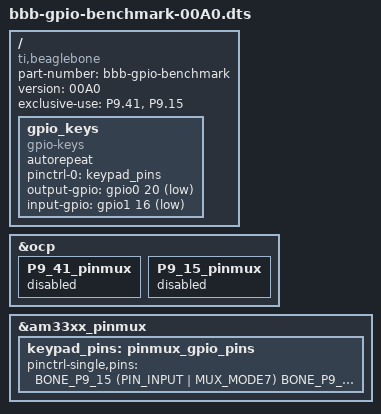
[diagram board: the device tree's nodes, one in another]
/dts-v1/;
/plugin/;        

#include <dt-bindings/board/am335x-bbw-bbb-base.h>
#include <dt-bindings/gpio/gpio.h>
#include <dt-bindings/pinctrl/am33xx.h>

/ {
    compatible = "ti,beaglebone", "ti,beaglebone-black";

    part-number = "bbb-gpio-benchmark";
    version = "00A0";

    exclusive-use =
        "P9.41",
        "P9.15";

    // Free up the pins from the pinmux helper
    fragment@0 {
        target = <&ocp>;
        __overlay__ {
            P9_41_pinmux { status = "disabled"; };
            P9_15_pinmux { status = "disabled"; };
        };
    };

    fragment@1 {
        target = <&am33xx_pinmux>;
        __overlay__ {
            keypad_pins: pinmux_gpio_pins {
                pinctrl-single,pins = <
                    BONE_P9_15 (PIN_INPUT  | MUX_MODE7)
                    BONE_P9_41 (PIN_OUTPUT | MUX_MODE7)
                >;
            };
        };
    };

    fragment@2 {
        target-path = "/";
        __overlay__ {
            gpio_keys {
                compatible = "gpio-keys";
                autorepeat;
                pinctrl-names = "default";
                pinctrl-0 = <&keypad_pins>;

                output-gpio = <&gpio0 20 GPIO_ACTIVE_LOW>;
                input-gpio = <&gpio1 16 GPIO_ACTIVE_LOW>;
            };
        };
    };
};
